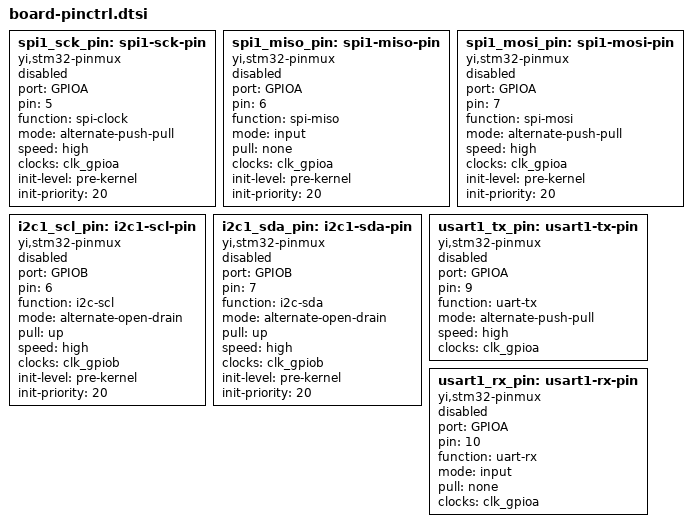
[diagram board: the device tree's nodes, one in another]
    spi1_sck_pin: spi1-sck-pin {
        compatible = "yi,stm32-pinmux";
        port = "GPIOA";
        pin = <5>;
        function = "spi-clock";
        mode = "alternate-push-pull";
        speed = "high";
        clocks = <&clk_gpioa>;
        init-level = "pre-kernel";
        init-priority = <20>;
        status = "available";
    };

    spi1_miso_pin: spi1-miso-pin {
        compatible = "yi,stm32-pinmux";
        port = "GPIOA";
        pin = <6>;
        function = "spi-miso";
        mode = "input";
        pull = "none";
        clocks = <&clk_gpioa>;
        init-level = "pre-kernel";
        init-priority = <20>;
        status = "available";
    };

    spi1_mosi_pin: spi1-mosi-pin {
        compatible = "yi,stm32-pinmux";
        port = "GPIOA";
        pin = <7>;
        function = "spi-mosi";
        mode = "alternate-push-pull";
        speed = "high";
        clocks = <&clk_gpioa>;
        init-level = "pre-kernel";
        init-priority = <20>;
        status = "available";
    };

    i2c1_scl_pin: i2c1-scl-pin {
        compatible = "yi,stm32-pinmux";
        port = "GPIOB";
        pin = <6>;
        function = "i2c-scl";
        mode = "alternate-open-drain";
        pull = "up";
        speed = "high";
        clocks = <&clk_gpiob>;
        init-level = "pre-kernel";
        init-priority = <20>;
        status = "available";
    };

    i2c1_sda_pin: i2c1-sda-pin {
        compatible = "yi,stm32-pinmux";
        port = "GPIOB";
        pin = <7>;
        function = "i2c-sda";
        mode = "alternate-open-drain";
        pull = "up";
        speed = "high";
        clocks = <&clk_gpiob>;
        init-level = "pre-kernel";
        init-priority = <20>;
        status = "available";
    };

    usart1_tx_pin: usart1-tx-pin {
        compatible = "yi,stm32-pinmux";
        port = "GPIOA";
        pin = <9>;
        function = "uart-tx";
        mode = "alternate-push-pull";
        speed = "high";
        clocks = <&clk_gpioa>;
        status = "available";
    };

    usart1_rx_pin: usart1-rx-pin {
        compatible = "yi,stm32-pinmux";
        port = "GPIOA";
        pin = <10>;
        function = "uart-rx";
        mode = "input";
        pull = "none";
        clocks = <&clk_gpioa>;
        status = "available";
    };
